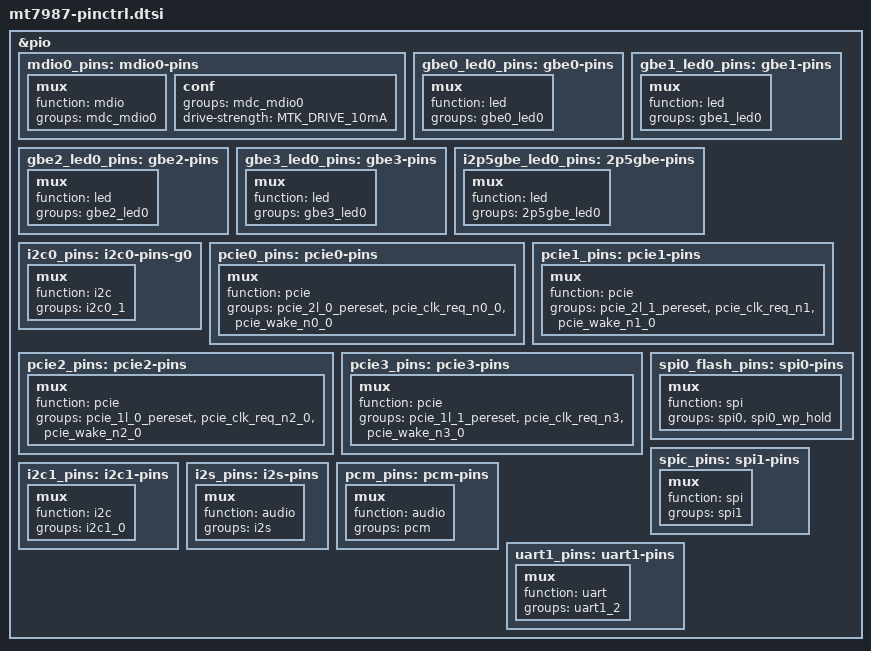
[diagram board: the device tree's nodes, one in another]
// SPDX-License-Identifier: (GPL-2.0 OR MIT)
/*
 * Copyright (C) 2023 MediaTek Inc.
 * Author: Sam.Shih <sam.shih@mediatek.com>
 */

&pio {
	mdio0_pins: mdio0-pins {
		mux {
			function = "mdio";
			groups = "mdc_mdio0";
		};

		conf {
			groups = "mdc_mdio0";
			drive-strength = <MTK_DRIVE_10mA>;
		};
	};

	gbe0_led0_pins: gbe0-pins {
		mux {
			function = "led";
			groups = "gbe0_led0";
		};
	};

	gbe1_led0_pins: gbe1-pins {
		mux {
			function = "led";
			groups = "gbe1_led0";
		};
	};

	gbe2_led0_pins: gbe2-pins {
		mux {
			function = "led";
			groups = "gbe2_led0";
		};
	};

	gbe3_led0_pins: gbe3-pins {
		mux {
			function = "led";
			groups = "gbe3_led0";
		};
	};

	i2p5gbe_led0_pins: 2p5gbe-pins {
		mux {
			function = "led";
			groups = "2p5gbe_led0";
		};
	};

	i2c0_pins: i2c0-pins-g0 {
		mux {
			function = "i2c";
			groups = "i2c0_1";
		};
	};

	pcie0_pins: pcie0-pins {
		mux {
			function = "pcie";
			groups = "pcie_2l_0_pereset", "pcie_clk_req_n0_0",
				 "pcie_wake_n0_0";
		};
	};

	pcie1_pins: pcie1-pins {
		mux {
			function = "pcie";
			groups = "pcie_2l_1_pereset", "pcie_clk_req_n1",
				 "pcie_wake_n1_0";
		};
	};

	pcie2_pins: pcie2-pins {
		mux {
			function = "pcie";
			groups = "pcie_1l_0_pereset", "pcie_clk_req_n2_0",
				 "pcie_wake_n2_0";
		};
	};

	pcie3_pins: pcie3-pins {
		mux {
			function = "pcie";
			groups = "pcie_1l_1_pereset", "pcie_clk_req_n3",
				 "pcie_wake_n3_0";
		};
	};

	spi0_flash_pins: spi0-pins {
		mux {
			function = "spi";
			groups = "spi0", "spi0_wp_hold";
		};
	};

	spic_pins: spi1-pins {
		mux {
			function = "spi";
			groups = "spi1";
		};
	};

	i2c1_pins: i2c1-pins {
		mux {
			function = "i2c";
			groups = "i2c1_0";
		};
	};

	i2s_pins: i2s-pins {
		mux {
			function = "audio";
			groups = "i2s";
		};
	};

	pcm_pins: pcm-pins {
		mux {
			function = "audio";
			groups = "pcm";
		};
	};

	uart1_pins: uart1-pins {
		mux {
			function = "uart";
			groups = "uart1_2";
		};
	};
};
